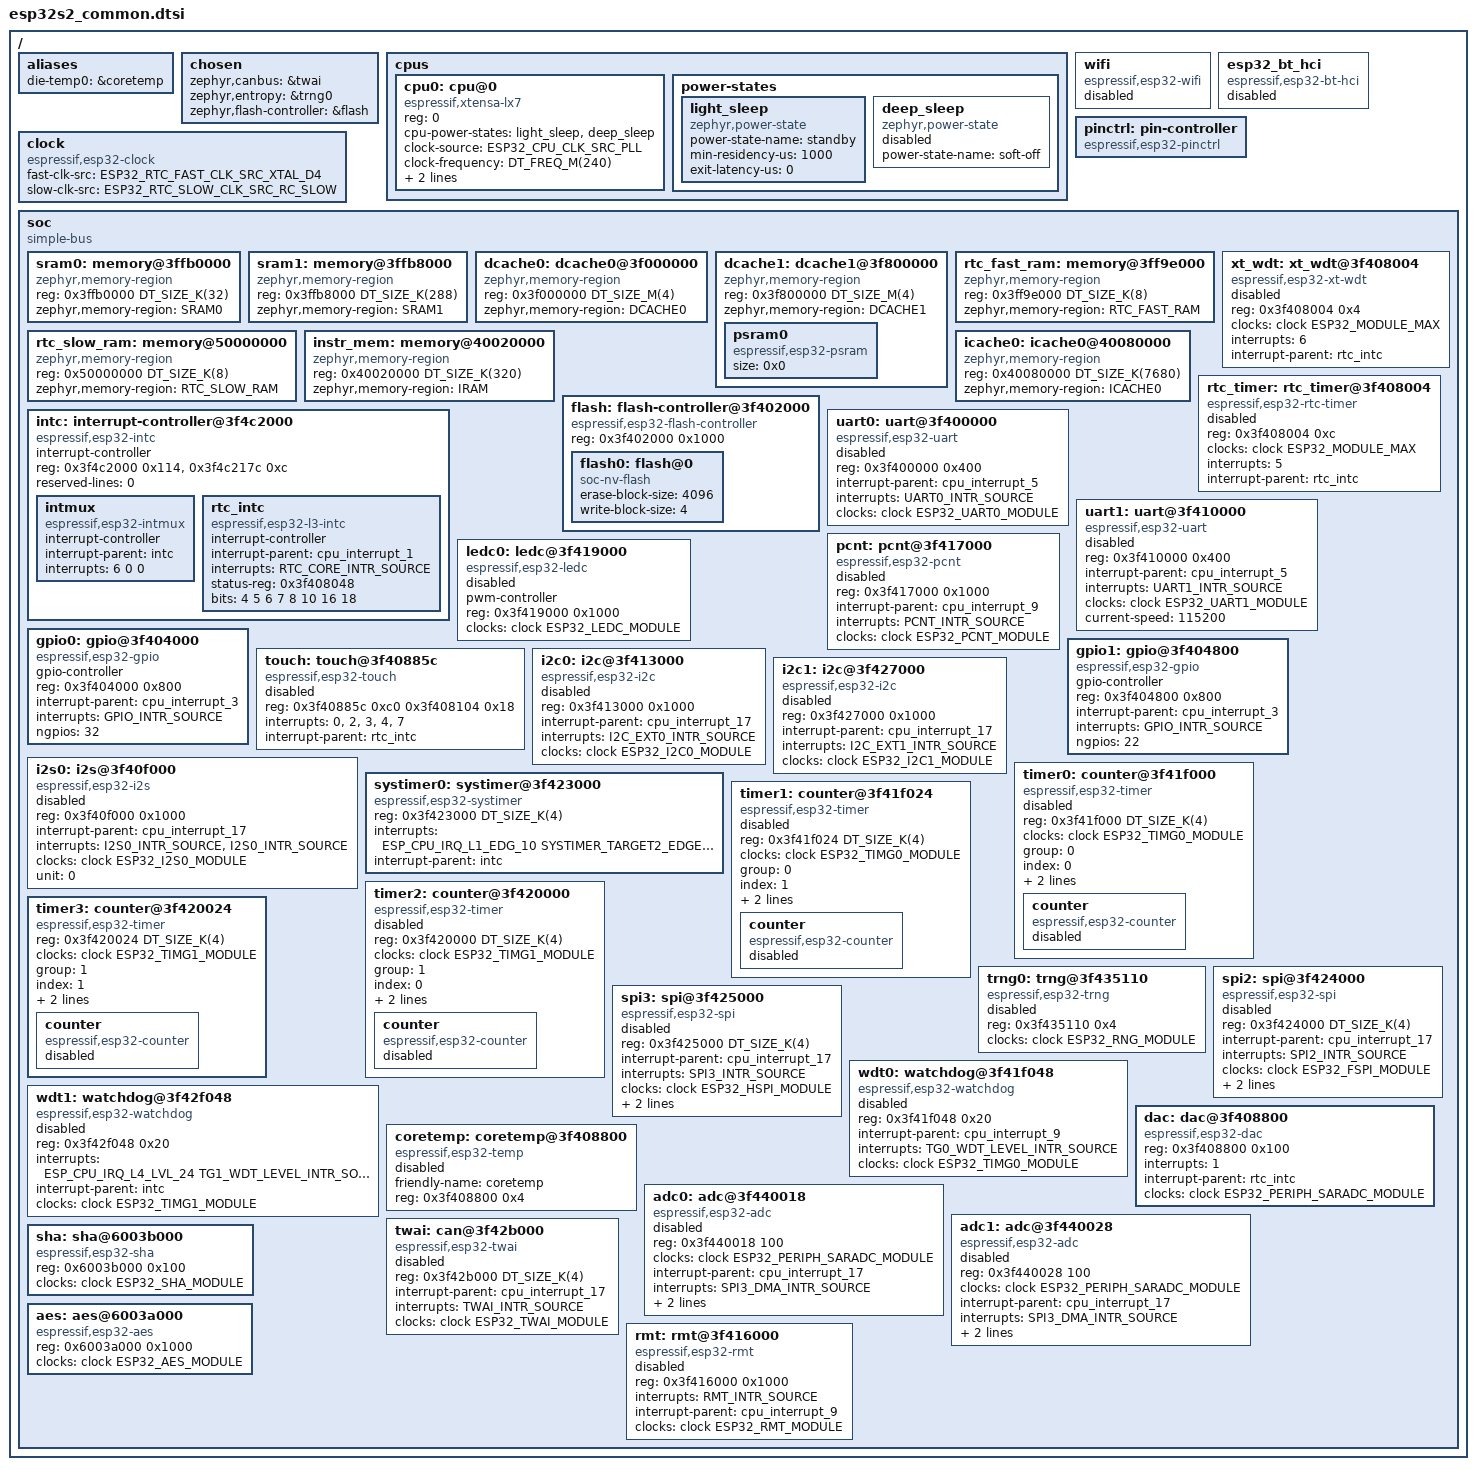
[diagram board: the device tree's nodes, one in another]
/*
 * Copyright (c) 2021 Espressif Systems (Shanghai) Co., Ltd.
 *
 * SPDX-License-Identifier: Apache-2.0
 */
#include <mem.h>
#include <freq.h>
#include <xtensa/xtensa.dtsi>
#include <zephyr/dt-bindings/adc/adc.h>
#include <zephyr/dt-bindings/gpio/gpio.h>
#include <zephyr/dt-bindings/i2c/i2c.h>
#include <zephyr/dt-bindings/clock/esp32s2_clock.h>
#include <zephyr/dt-bindings/interrupt-controller/espressif-esp32s2-intmux.h>
#include <zephyr/dt-bindings/pinctrl/esp32-pinctrl.h>

/ {
	#address-cells = <1>;
	#size-cells = <1>;

	aliases {
		die-temp0 = &coretemp;
	};

	chosen {
		zephyr,canbus = &twai;
		zephyr,entropy = &trng0;
		zephyr,flash-controller = &flash;
	};

	cpus {
		#address-cells = <1>;
		#size-cells = <0>;

		cpu0: cpu@0 {
			device_type = "cpu";
			compatible = "espressif,xtensa-lx7";
			reg = <0>;
			cpu-power-states = <&light_sleep &deep_sleep>;
			clock-source = <ESP32_CPU_CLK_SRC_PLL>;
			clock-frequency = <DT_FREQ_M(240)>;
			xtal-freq = <DT_FREQ_M(40)>;
			d-cache-line-size = <4>;
		};

		power-states {
			light_sleep: light_sleep {
				compatible = "zephyr,power-state";
				power-state-name = "standby";
				min-residency-us = <1000>;
				exit-latency-us = <0>;
			};

			deep_sleep: deep_sleep {
				/* Deep sleep must be entered using pm_state_force()
				 * or sys_poweroff() calls only
				 */
				compatible = "zephyr,power-state";
				power-state-name = "soft-off";
				status = "disabled";
			};
		};
	};

	wifi: wifi {
		compatible = "espressif,esp32-wifi";
		status = "disabled";
	};

	esp32_bt_hci: esp32_bt_hci {
		compatible = "espressif,esp32-bt-hci";
		status = "disabled";
	};

	pinctrl: pin-controller {
		compatible = "espressif,esp32-pinctrl";
		status = "okay";
	};

	clock: clock {
		compatible = "espressif,esp32-clock";
		fast-clk-src = <ESP32_RTC_FAST_CLK_SRC_XTAL_D4>;
		slow-clk-src = <ESP32_RTC_SLOW_CLK_SRC_RC_SLOW>;
		#clock-cells = <1>;
		status = "okay";
	};

	soc {
		#address-cells = <1>;
		#size-cells = <1>;
		compatible = "simple-bus";
		ranges;

		sram0: memory@3ffb0000 {
			compatible = "zephyr,memory-region", "mmio-sram";
			reg = <0x3ffb0000 DT_SIZE_K(32)>;
			zephyr,memory-region = "SRAM0";
		};

		sram1: memory@3ffb8000 {
			compatible = "zephyr,memory-region", "mmio-sram";
			reg = <0x3ffb8000 DT_SIZE_K(288)>;
			zephyr,memory-region = "SRAM1";
		};

		dcache0: dcache0@3f000000 {
			compatible = "zephyr,memory-region";
			reg = <0x3f000000 DT_SIZE_M(4)>;
			zephyr,memory-region = "DCACHE0";
		};

		dcache1: dcache1@3f800000 {
			compatible = "zephyr,memory-region";
			reg = <0x3f800000 DT_SIZE_M(4)>;
			zephyr,memory-region = "DCACHE1";

			psram0: psram0 {
				compatible = "espressif,esp32-psram";
				size = <0x0>;
			};
		};

		rtc_fast_ram: memory@3ff9e000 {
			compatible = "zephyr,memory-region", "mmio-sram";
			reg = <0x3ff9e000 DT_SIZE_K(8)>;
			zephyr,memory-region = "RTC_FAST_RAM";
		};

		rtc_slow_ram: memory@50000000 {
			compatible = "zephyr,memory-region", "mmio-sram";
			reg = <0x50000000 DT_SIZE_K(8)>;
			zephyr,memory-region = "RTC_SLOW_RAM";
		};

		instr_mem: memory@40020000 {
			compatible = "zephyr,memory-region";
			reg = <0x40020000 DT_SIZE_K(320)>;
			zephyr,memory-region = "IRAM";
		};

		icache0: icache0@40080000 {
			compatible = "zephyr,memory-region";
			reg = <0x40080000 DT_SIZE_K(7680)>;
			zephyr,memory-region = "ICACHE0";
		};

		xt_wdt: xt_wdt@3f408004 {
			compatible = "espressif,esp32-xt-wdt";
			reg = <0x3f408004 0x4>;
			clocks = <&clock ESP32_MODULE_MAX>;
			interrupts = <6>;	/* bit 16, RTC_CNTL_XTAL32K_DEAD */
			interrupt-parent = <&rtc_intc>;
			status = "disabled";
		};

		rtc_timer: rtc_timer@3f408004 {
			reg = <0x3f408004 0xc>;
			compatible = "espressif,esp32-rtc-timer";
			clocks = <&clock ESP32_MODULE_MAX>;
			interrupts = <5>;	/* bit 10, RTC_CNTL_MAIN_TIMER */
			interrupt-parent = <&rtc_intc>;
			status = "disabled";
		};

		flash: flash-controller@3f402000 {
			compatible = "espressif,esp32-flash-controller";
			reg = <0x3f402000 0x1000>;

			#address-cells = <1>;
			#size-cells = <1>;
			ranges;

			flash0: flash@0 {
				compatible = "soc-nv-flash";
				erase-block-size = <4096>;
				write-block-size = <4>;
				#address-cells = <1>;
				#size-cells = <1>;
				/* reg and ranges are specified in SOC/SIP dtsi */
			};
		};

		intc: interrupt-controller@3f4c2000 {
			compatible = "espressif,esp32-intc";
			#interrupt-cells = <3>;
			#address-cells = <0>;
			interrupt-controller;
			/* INTMUX MAP base then pending-STATUS base */
			reg = <0x3f4c2000 0x114>, <0x3f4c217c 0xc>;
			reg-names = "map0", "status0";
			/* Connected at run time by the Wi-Fi library */
			reserved-lines = <0>;
			status = "okay";

			/* The one level-2 aggregator. Line 6 is the internal CPU
			 * timer line, so no matrix source is ever routed to it;
			 * it is only the key in the level-1 field of every
			 * level-2 IRQ number (CONFIG_2ND_LVL_INTR_00_OFFSET).
			 */
			intmux: intmux {
				compatible = "espressif,esp32-intmux";
				interrupt-controller;
				#interrupt-cells = <2>;
				#address-cells = <0>;
				interrupt-parent = <&intc>;
				interrupts = <6 0 0>;
			};

			ESP_CPU_INTERRUPT(1)	/* RTC peripherals */
			ESP_CPU_INTERRUPT(3)	/* GPIO */
			ESP_CPU_INTERRUPT(5)	/* UART */
			ESP_CPU_INTERRUPT(9)	/* timer groups, PCNT, RMT */
			ESP_CPU_INTERRUPT(17)	/* I2C, I2S, SPI, ADC, TWAI */

			rtc_intc: rtc_intc {
				compatible = "espressif,esp32-l3-intc";
				interrupt-controller;
				#interrupt-cells = <1>;
				interrupt-parent = <&cpu_interrupt_1>;
				interrupts = <RTC_CORE_INTR_SOURCE>;
				status-reg = <0x3f408048>;	/* RTC_CNTL_INT_ST_REG */
				bits = <4 5 6 7 8 10 16 18>;
			};
		};

		uart0: uart@3f400000 {
			compatible = "espressif,esp32-uart";
			reg = <0x3f400000 0x400>;
			status = "disabled";
			interrupt-parent = <&cpu_interrupt_5>;
			interrupts = <UART0_INTR_SOURCE>;
			clocks = <&clock ESP32_UART0_MODULE>;
		};

		uart1: uart@3f410000 {
			compatible = "espressif,esp32-uart";
			reg = <0x3f410000 0x400>;
			status = "disabled";
			interrupt-parent = <&cpu_interrupt_5>;
			interrupts = <UART1_INTR_SOURCE>;
			clocks = <&clock ESP32_UART1_MODULE>;
			current-speed = <115200>;
		};

		pcnt: pcnt@3f417000 {
			compatible = "espressif,esp32-pcnt";
			reg = <0x3f417000 0x1000>;
			interrupt-parent = <&cpu_interrupt_9>;
			interrupts = <PCNT_INTR_SOURCE>;
			clocks = <&clock ESP32_PCNT_MODULE>;
			status = "disabled";
		};

		ledc0: ledc@3f419000 {
			compatible = "espressif,esp32-ledc";
			pwm-controller;
			#pwm-cells = <3>;
			reg = <0x3f419000 0x1000>;
			clocks = <&clock ESP32_LEDC_MODULE>;
			status = "disabled";
		};

		gpio0: gpio@3f404000 {
			compatible = "espressif,esp32-gpio";
			gpio-controller;
			#gpio-cells = <2>;
			reg = <0x3f404000 0x800>;
			interrupt-parent = <&cpu_interrupt_3>;
			interrupts = <GPIO_INTR_SOURCE>;
			/* Maximum available pins (per port)
			 * Actual occupied pins are specified
			 * on part number dtsi level, using
			 * the `gpio-reserved-ranges` property.
			 */
			ngpios = <32>;   /* 0..31 */
		};

		gpio1: gpio@3f404800 {
			compatible = "espressif,esp32-gpio";
			gpio-controller;
			#gpio-cells = <2>;
			reg = <0x3f404800 0x800>;
			interrupt-parent = <&cpu_interrupt_3>;
			interrupts = <GPIO_INTR_SOURCE>;
			ngpios = <22>;   /* 32..53 */
		};

		touch: touch@3f40885c {
			compatible = "espressif,esp32-touch";
			reg = <0x3f40885c 0xc0 0x3f408104 0x18>;
			interrupts = <0>,	/* bit 4, RTC_CNTL_TOUCH_SCAN_DONE */
				     <2>,	/* bit 6, RTC_CNTL_TOUCH_DONE */
				     <3>,	/* bit 7, RTC_CNTL_TOUCH_ACTIVE */
				     <4>,	/* bit 8, RTC_CNTL_TOUCH_INACTIVE */
				     <7>;	/* bit 18, RTC_CNTL_TOUCH_TIMEOUT */
			interrupt-parent = <&rtc_intc>;
			status = "disabled";
		};

		i2c0: i2c@3f413000 {
			compatible = "espressif,esp32-i2c";
			#address-cells = <1>;
			#size-cells = <0>;
			reg = <0x3f413000 0x1000>;
			interrupt-parent = <&cpu_interrupt_17>;
			interrupts = <I2C_EXT0_INTR_SOURCE>;
			clocks = <&clock ESP32_I2C0_MODULE>;
			status = "disabled";
		};

		i2c1: i2c@3f427000 {
			compatible = "espressif,esp32-i2c";
			#address-cells = <1>;
			#size-cells = <0>;
			reg = <0x3f427000 0x1000>;
			interrupt-parent = <&cpu_interrupt_17>;
			interrupts = <I2C_EXT1_INTR_SOURCE>;
			clocks = <&clock ESP32_I2C1_MODULE>;
			status = "disabled";
		};

		i2s0: i2s@3f40f000 {
			compatible = "espressif,esp32-i2s";
			#address-cells = <1>;
			#size-cells = <0>;
			reg = <0x3f40f000 0x1000>;
			interrupt-parent = <&cpu_interrupt_17>;
			interrupts = <I2S0_INTR_SOURCE>, <I2S0_INTR_SOURCE>;
			interrupt-names = "rx", "tx";
			clocks = <&clock ESP32_I2S0_MODULE>;
			unit = <0>;
			status = "disabled";
		};

		timer0: counter@3f41f000 {
			compatible = "espressif,esp32-timer";
			reg = <0x3f41f000 DT_SIZE_K(4)>;
			clocks = <&clock ESP32_TIMG0_MODULE>;
			group = <0>;
			index = <0>;
			interrupt-parent = <&cpu_interrupt_9>;
			interrupts = <TG0_T0_LEVEL_INTR_SOURCE>;
			status = "disabled";

			counter {
				compatible = "espressif,esp32-counter";
				status = "disabled";
			};
		};

		systimer0: systimer@3f423000 {
			compatible = "espressif,esp32-systimer";
			reg = <0x3f423000 DT_SIZE_K(4)>;
			interrupts = <ESP_CPU_IRQ_L1_EDG_10 SYSTIMER_TARGET2_EDGE_INTR_SOURCE 0>;
			interrupt-parent = <&intc>;
			status = "okay";
		};

		timer1: counter@3f41f024 {
			compatible = "espressif,esp32-timer";
			reg = <0x3f41f024 DT_SIZE_K(4)>;
			clocks = <&clock ESP32_TIMG0_MODULE>;
			group = <0>;
			index = <1>;
			interrupt-parent = <&cpu_interrupt_9>;
			interrupts = <TG0_T1_LEVEL_INTR_SOURCE>;
			status = "disabled";

			counter {
				compatible = "espressif,esp32-counter";
				status = "disabled";
			};
		};

		timer2: counter@3f420000 {
			compatible = "espressif,esp32-timer";
			reg = <0x3f420000 DT_SIZE_K(4)>;
			clocks = <&clock ESP32_TIMG1_MODULE>;
			group = <1>;
			index = <0>;
			interrupt-parent = <&cpu_interrupt_9>;
			interrupts = <TG1_T0_LEVEL_INTR_SOURCE>;
			status = "disabled";

			counter {
				compatible = "espressif,esp32-counter";
				status = "disabled";
			};
		};

		timer3: counter@3f420024 {
			compatible = "espressif,esp32-timer";
			reg = <0x3f420024 DT_SIZE_K(4)>;
			clocks = <&clock ESP32_TIMG1_MODULE>;
			group = <1>;
			index = <1>;
			interrupt-parent = <&cpu_interrupt_9>;
			interrupts = <TG1_T1_LEVEL_INTR_SOURCE>;

			counter {
				compatible = "espressif,esp32-counter";
				status = "disabled";
			};
		};

		trng0: trng@3f435110 {
			compatible = "espressif,esp32-trng";
			reg = <0x3f435110 0x4>;
			clocks = <&clock ESP32_RNG_MODULE>;
			status = "disabled";
		};

		spi2: spi@3f424000 {
			compatible = "espressif,esp32-spi";
			reg = <0x3f424000 DT_SIZE_K(4)>;
			interrupt-parent = <&cpu_interrupt_17>;
			interrupts = <SPI2_INTR_SOURCE>;
			clocks = <&clock ESP32_FSPI_MODULE>;
			dma-clk = <ESP32_SPI2_DMA_MODULE>;
			dma-host = <0>;
			status = "disabled";
		};

		spi3: spi@3f425000 {
			compatible = "espressif,esp32-spi";
			reg = <0x3f425000 DT_SIZE_K(4)>;
			interrupt-parent = <&cpu_interrupt_17>;
			interrupts = <SPI3_INTR_SOURCE>;
			clocks = <&clock ESP32_HSPI_MODULE>;
			dma-clk = <ESP32_SPI3_DMA_MODULE>;
			dma-host = <1>;
			status = "disabled";
		};

		wdt0: watchdog@3f41f048 {
			compatible = "espressif,esp32-watchdog";
			reg = <0x3f41f048 0x20>;
			interrupt-parent = <&cpu_interrupt_9>;
			interrupts = <TG0_WDT_LEVEL_INTR_SOURCE>;
			clocks = <&clock ESP32_TIMG0_MODULE>;
			status = "disabled";
		};

		wdt1: watchdog@3f42f048 {
			compatible = "espressif,esp32-watchdog";
			reg = <0x3f42f048 0x20>;
			interrupts = <ESP_CPU_IRQ_L4_LVL_24 TG1_WDT_LEVEL_INTR_SOURCE 0>;
			interrupt-parent = <&intc>;
			clocks = <&clock ESP32_TIMG1_MODULE>;
			status = "disabled";
		};

		dac: dac@3f408800 {
			compatible = "espressif,esp32-dac";
			reg = <0x3f408800 0x100>;
			interrupts = <1>;	/* bit 5, not connected yet */
			interrupt-parent = <&rtc_intc>;
			clocks = <&clock ESP32_PERIPH_SARADC_MODULE>;
			#io-channel-cells = <1>;
		};

		coretemp: coretemp@3f408800 {
			compatible = "espressif,esp32-temp";
			friendly-name = "coretemp";
			reg = <0x3f408800 0x4>;
			status = "disabled";
		};

		adc0: adc@3f440018 {
			compatible = "espressif,esp32-adc";
			reg = <0x3f440018 100>;
			clocks = <&clock ESP32_PERIPH_SARADC_MODULE>;
			interrupt-parent = <&cpu_interrupt_17>;
			interrupts = <SPI3_DMA_INTR_SOURCE>;
			unit = <1>;
			channel-count = <10>;
			#io-channel-cells = <1>;
			status = "disabled";
		};

		adc1: adc@3f440028 {
			compatible = "espressif,esp32-adc";
			reg = <0x3f440028 100>;
			clocks = <&clock ESP32_PERIPH_SARADC_MODULE>;
			interrupt-parent = <&cpu_interrupt_17>;
			interrupts = <SPI3_DMA_INTR_SOURCE>;
			unit = <2>;
			channel-count = <10>;
			#io-channel-cells = <1>;
			status = "disabled";
		};

		twai: can@3f42b000 {
			compatible = "espressif,esp32-twai";
			reg = <0x3f42b000 DT_SIZE_K(4)>;
			interrupt-parent = <&cpu_interrupt_17>;
			interrupts = <TWAI_INTR_SOURCE>;
			clocks = <&clock ESP32_TWAI_MODULE>;
			status = "disabled";
		};

		sha: sha@6003b000 {
			compatible = "espressif,esp32-sha";
			reg = <0x6003b000 0x100>;
			clocks = <&clock ESP32_SHA_MODULE>;
			status = "okay";
		};

		aes: aes@6003a000 {
			compatible = "espressif,esp32-aes";
			reg = <0x6003a000 0x1000>;
			clocks = <&clock ESP32_AES_MODULE>;
			status = "okay";
		};

		rmt: rmt@3f416000 {
			compatible = "espressif,esp32-rmt";
			#pulse-io-cells = <1>;
			reg = <0x3f416000 0x1000>;
			interrupts = <RMT_INTR_SOURCE>;
			interrupt-parent = <&cpu_interrupt_9>;
			clocks = <&clock ESP32_RMT_MODULE>;
			status = "disabled";
		};
	};
};
